# CY8C5868AXI_LP035 register map
File version: 0.1
CY8C58LP
Registers are 8-bit, read-write, no defined reset value unless marked. A register's access mark holds for its fields unless they carry their own. Offsets are from the block's base; lines under a group give offsets from that group; [hi:lo] are bit positions; {n}, {i} and the like mark numbered series; 'fields as' and 'values as' point back to an identical list; <NAME> marks a mode.

## Memory map
0x400043A4 WaveDAC8_1_BuffAmp size 0x17A2
0x400043A8 VDAC8_2 size 0x17DB
0x400043A8 WaveDAC8_1_VDAC8 size 0x17DA
0x400043A8 IDAC8_1 size 0x17D9
0x400043A8 VDAC8_1 size 0x17DC
0x400043AA ADC_DelSig_1 size 0x17E0
0x40004614 ADC_SAR_Seq_1_SAR size 0x158D — SAR ADC
0x40004616 ADC_SAR_1 size 0x158D — SAR ADC
0x400049C8 I2C_1 size 0x19
0x40006409 SPIS_1 size 0x63
0x40006420 PWM_1 size 0x72
0x40006422 PWM_4 size 0x72
0x40006426 PWM_8 size 0x72
0x4000642A PWM_7 size 0x72
0x4000642C PWM_2 size 0x72
0x4000642E PWM_6 size 0x14D
0x40006461 Port_4_Status size 0x31
0x4000646E Port_2_Status size 0x31
0x40006471 Port_4_Control size 0x1
0x4000647A Port_12_Control size 0x1
0x4000647D Port_2_Control size 0x1
0x4000647F PWM_5 size 0x117
0x4000652A PWM_3 size 0x72
0x40006568 Port_12_Status size 0x31
0x4000656A Port_5_Status size 0x31
0x40006579 Port_5_Control size 0x1

## Port_2_Status
Base 0x4000646E
0x00 Port_2_Status_STATUS_REG
0x20 Port_2_Status_MASK_REG
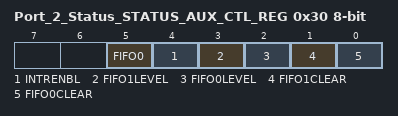
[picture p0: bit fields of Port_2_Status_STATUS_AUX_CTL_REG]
0x30 Port_2_Status_STATUS_AUX_CTL_REG
  [5] FIFO0 — FIFO0 clear
    1=ENABLED (Enable counter); 0=DISABLED (Disable counter)
  [4] INTRENBL — Enables or disables the Interrupt
    1=ENABLED (Interrupt enabled); 0=DISABLED (Interrupt disabled)
  [3] FIFO1LEVEL — FIFO level
    1=ENABLED (FIFO LVL: input mode: FIFO at least 1/2 empty; output mode: FIFO at least 1/2 full); 0=DISABLED (FIFO LVL: input mode: FIFO not full; output mode: FIFO not empty)
  [2] FIFO0LEVEL — FIFO level
    values as FIFO1LEVEL
  [1] FIFO1CLEAR — FIFO clear
    1=ENABLED (Clear FIFO state); 0=DISABLED (Normal FIFO operation)
  [0] FIFO0CLEAR — FIFO clear
    values as FIFO1CLEAR

## Port_12_Status
Base 0x40006568
Registers as Port_2_Status (with Port_2_Status read as Port_12_Status).

## Port_4_Status
Base 0x40006461
Registers as Port_2_Status (with Port_2_Status read as Port_4_Status).

## Port_5_Status
Base 0x4000656A
Registers as Port_2_Status (with Port_2_Status read as Port_5_Status).

## Port_2_Control
Base 0x4000647D
0x00 Port_2_Control_CONTROL_REG

## Port_12_Control
Base 0x4000647A
Registers as Port_2_Control (with Port_2_Control read as Port_12_Control).

## Port_4_Control
Base 0x40006471
Registers as Port_2_Control (with Port_2_Control read as Port_4_Control).

## Port_5_Control
Base 0x40006579
Registers as Port_2_Control (with Port_2_Control read as Port_5_Control).

## PWM_1
Base 0x40006420
0x00 PWM_1_COMPARE_Reg 16-bit — UDB.D0 - Assigned Compare Value
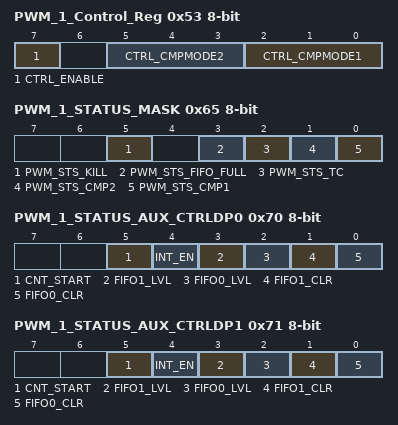
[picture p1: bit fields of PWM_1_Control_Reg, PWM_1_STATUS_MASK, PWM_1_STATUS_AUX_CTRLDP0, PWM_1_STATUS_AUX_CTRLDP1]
0x53 PWM_1_Control_Reg — UDB Control Register - Assigned Control Register Value
  [7] CTRL_ENABLE — Enable the PWM
  [5:3] CTRL_CMPMODE2 — Compare mode 2
  [2:0] CTRL_CMPMODE1 — Compare mode 1
0x65 PWM_1_STATUS_MASK — UDB Status bits Interrupt Mask Enable Register
  [5] PWM_STS_KILL ro — Enables the Interrupt on Kill
  [3] PWM_STS_FIFO_FULL ro — FIFO Full Status Mask
  [2] PWM_STS_TC ro — Enables the Interrupt on Terminal Count
  [1] PWM_STS_CMP2 ro — Enables the Interrupt on Compare 2
  [0] PWM_STS_CMP1 ro — Enables the Interrupt on Compare 1
0x70 PWM_1_STATUS_AUX_CTRLDP0 — UDB Auxilliary Control Register
  [5] CNT_START — FIFO0 clear
    0=E_CNT_START0 (Disable counter); 1=E_CNT_START1 (Enable counter)
  [4] INT_EN
    0=E_INT_EN0 (Interrupt disabled); 1=E_INT_EN1 (Interrupt enabled)
  [3] FIFO1_LVL — FIFO level
    0=E_FIFO_LVL_0 (FIFO LVL: input mode: FIFO not full; output mode: FIFO not empty); 1=E_FIFO_LVL_1 (FIFO LVL: input mode: FIFO at least 1/2 empty; output mode: FIFO at least 1/2 full)
  [2] FIFO0_LVL — FIFO level
    values as FIFO1_LVL
  [1] FIFO1_CLR — FIFO1 clear
    0=E_FIFO_CLR_0 (Normal FIFO operation); 1=E_FIFO_CLR_1 (Clear FIFO state)
  [0] FIFO0_CLR — FIFO0 clear
    values as FIFO1_CLR
0x71 PWM_1_STATUS_AUX_CTRLDP1 — UDB Auxilliary Control Register
  fields as PWM_1_STATUS_AUX_CTRLDP0

## PWM_2
Base 0x4000642C
Registers as PWM_1 (with PWM_1 read as PWM_2), without PWM_1_Control_Reg, PWM_1_STATUS_MASK; these are added or differ:
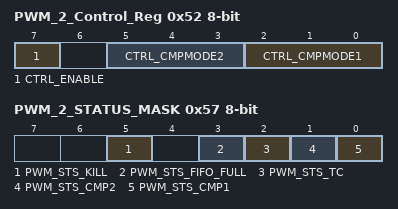
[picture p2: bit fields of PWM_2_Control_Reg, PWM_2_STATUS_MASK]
0x52 PWM_2_Control_Reg — UDB Control Register - Assigned Control Register Value
  [7] CTRL_ENABLE — Enable the PWM
  [5:3] CTRL_CMPMODE2 — Compare mode 2
  [2:0] CTRL_CMPMODE1 — Compare mode 1
0x57 PWM_2_STATUS_MASK — UDB Status bits Interrupt Mask Enable Register
  fields as PWM_1.PWM_1_STATUS_MASK

## PWM_3
Base 0x4000652A
Registers as PWM_1 (with PWM_1 read as PWM_3), without PWM_1_Control_Reg, PWM_1_STATUS_MASK; these are added or differ:
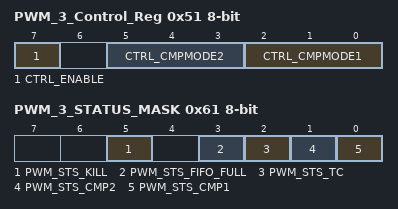
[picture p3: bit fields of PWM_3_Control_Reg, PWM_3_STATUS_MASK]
0x51 PWM_3_Control_Reg — UDB Control Register - Assigned Control Register Value
  [7] CTRL_ENABLE — Enable the PWM
  [5:3] CTRL_CMPMODE2 — Compare mode 2
  [2:0] CTRL_CMPMODE1 — Compare mode 1
0x61 PWM_3_STATUS_MASK — UDB Status bits Interrupt Mask Enable Register
  fields as PWM_1.PWM_1_STATUS_MASK

## PWM_4
Base 0x40006422
Registers as PWM_1 (with PWM_1 read as PWM_4), without PWM_1_Control_Reg; these are added or differ:
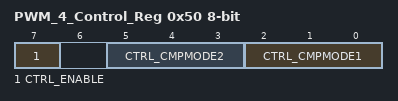
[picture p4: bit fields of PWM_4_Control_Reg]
0x50 PWM_4_Control_Reg — UDB Control Register - Assigned Control Register Value
  [7] CTRL_ENABLE — Enable the PWM
  [5:3] CTRL_CMPMODE2 — Compare mode 2
  [2:0] CTRL_CMPMODE1 — Compare mode 1

## PWM_8
Base 0x40006426
Registers as PWM_2 (with PWM_2 read as PWM_8), without PWM_2_STATUS_MASK; these are added or differ:
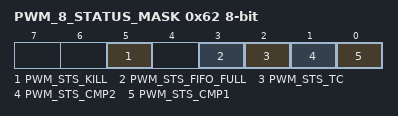
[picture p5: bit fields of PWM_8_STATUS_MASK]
0x62 PWM_8_STATUS_MASK — UDB Status bits Interrupt Mask Enable Register
  fields as PWM_1.PWM_1_STATUS_MASK

## PWM_6
Base 0x4000642E
Registers as PWM_3 (with PWM_3 read as PWM_6), without PWM_3_Control_Reg; these are added or differ:
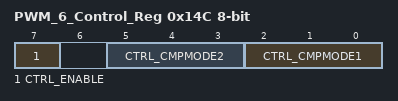
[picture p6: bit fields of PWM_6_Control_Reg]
0x14C PWM_6_Control_Reg — UDB Control Register - Assigned Control Register Value
  [7] CTRL_ENABLE — Enable the PWM
  [5:3] CTRL_CMPMODE2 — Compare mode 2
  [2:0] CTRL_CMPMODE1 — Compare mode 1

## PWM_7
Base 0x4000642A
Registers as PWM_8 (with PWM_8 read as PWM_7).
